# Template register map
Vendor: VendorName Co.Ltd; Series: SeriesName; File version: 1.2
CPU: CM7 r0p1, little endian, MPU, FPU, 4 interrupt priority bits
Registers are 32-bit, read-write, no defined reset value unless marked. A register's access mark holds for its fields unless they carry their own. Offsets are from the block's base; [hi:lo] are bit positions; {n}, {i} and the like mark numbered series; 'fields as' and 'values as' point back to an identical list.

## RCC — Reset And Clock Control
Base 0x400B0000
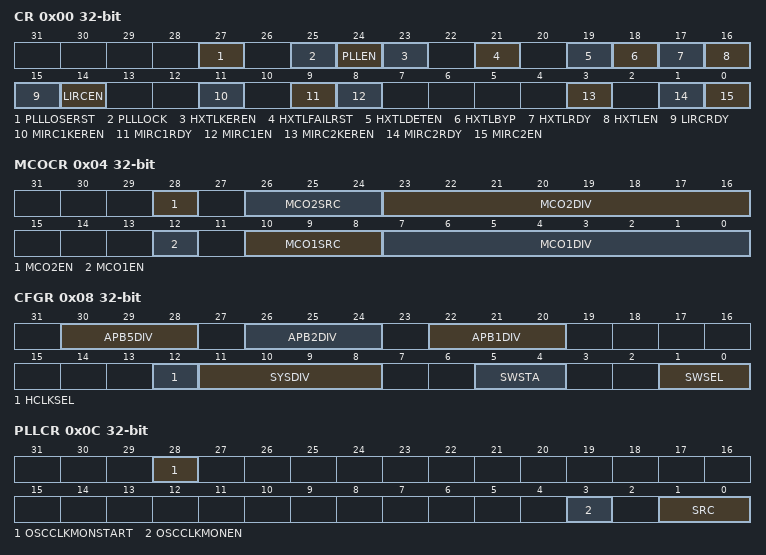
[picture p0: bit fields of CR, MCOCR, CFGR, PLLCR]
0x00 CR — RCC control register
  [27] PLLLOSERST — RCC PLLLOSERST bit: PLL lose of lock reset enable
  [25] PLLLOCK ro — RCC PLLLOCK bit: PLL lock flag
  [24] PLLEN — RCC PLLEN bit: PLL module enable
  [23] HXTLKEREN — RCC HXTLKEREN bit: kernal use HXTL clock oscillator enable
  [21] HXTLFAILRST — RCC HXTLFAILRST bit: HXTL failure reset enable
  [19] HXTLDETEN — RCC HXTLDETEN bit: HXTL clock check module control
  [18] HXTLBYP — RCC HXTLBYP bit: HXTL bypass config
  [17] HXTLRDY ro — RCC HXTLRDY bit: HXTL clock ready flag
  [16] HXTLEN — RCC HXTLEN bit: HXTL clock oscillator enable
  [15] LIRCRDY ro — RCC LIRCRDY bit: LIRC clock ready flag
  [14] LIRCEN — RCC LIRCEN bit: LIRC clock oscillator enable
  [11] MIRC1KEREN — RCC MIRC1KEREN bit: kernal use MIRC1 clock oscillator enable
  [9] MIRC1RDY ro — RCC MIRC1RDY bit: MIRC1 clock ready flag
  [8] MIRC1EN — RCC MIRC1EN bit: MIRC1 clock oscillator enable
  [3] MIRC2KEREN — RCC MIRC2KEREN bit: kernal use MIRC2 clock oscillator enable
  [1] MIRC2RDY ro — RCC MIRC2RDY bit: MIRC2 clock ready flag
  [0] MIRC2EN — RCC MIRC2EN bit: MIRC2 clock oscillator enable
0x04 MCOCR — RCC MCO config register
  [28] MCO2EN — RCC MCO2EN bit: MCO2 clock output enable
  [26:24] MCO2SRC — RCC MCO2SRC[2:0] bit: MCO2 clock output source select
  [23:16] MCO2DIV — RCC MCO2DIV[7:0] bit: MCO2 output frequency division set
  [12] MCO1EN — RCC MCO1EN bit: MCO1 clock output enable
  [10:8] MCO1SRC — RCC MCO1SRC[2:0] bit: MCO1 clock output source select
  [7:0] MCO1DIV — RCC MCO1DIV[7:0] bit: MCO1 output frequency division set
0x08 CFGR — RCC clock config register
  [30:28] APB5DIV — RCC APB5DIV[2:0] bit: APB5 clock frequency division set
  [26:24] APB2DIV — RCC APB2DIV[2:0] bit: APB2 clock frequency division set
  [22:20] APB1DIV — RCC APB1DIV[2:0] bit: APB1 clock frequency division set
  [12] HCLKSEL — RCC HCLKSEL bit: HCLK clock frequency division selection
  [11:8] SYSDIV — RCC SYSDIV[3:0] bit: system clock frequency division set
  [5:4] SWSTA ro — RCC SWSTA[1:0] bit: system clock switch status
  [1:0] SWSEL — RCC SWSEL[1:0] bit: system clock select control
0x0C PLLCR — RCC PLL control register
  [28] OSCCLKMONSTART — RCC OSCCLKMONSTART bit: OSCCLK stop monitor start bit
  [3] OSCCLKMONEN — RCC OSCCLKMONEN bit: OSCCLK stop monitor enable bit
  [1:0] SRC — RCC SRC[1:0] bit: PLL clock input source select
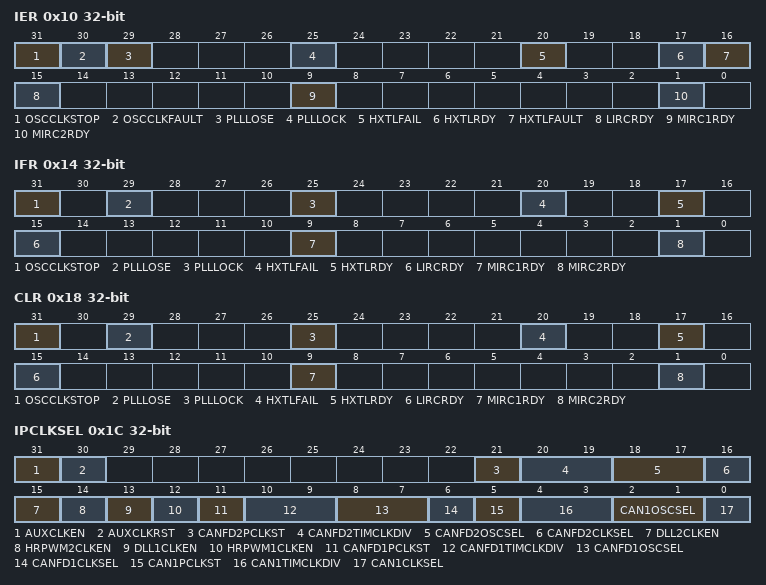
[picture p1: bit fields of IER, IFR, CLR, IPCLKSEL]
0x10 IER — RCC interrupt enable register
  [31] OSCCLKSTOP — RCC OSCCLKSTOP bit: OSCCLK stop interrupt enable
  [30] OSCCLKFAULT — RCC OSCCLKFAULT bit: OSCCLK fault interrupt function select
  [29] PLLLOSE — RCC PLLLOSE bit: PLL lose of lock interrupt enable
  [25] PLLLOCK — RCC PLLLOCK bit: PLL lock interrupt enable
  [20] HXTLFAIL — RCC HXTLFAIL bit: HXTL failure of oscillation interrupt enable
  [17] HXTLRDY — RCC HXTLRDY bit: HXTL ready interrupt enable
  [16] HXTLFAULT — RCC HXTLFAULT bit: HXTL fault interrupt function select
  [15] LIRCRDY — RCC LIRCRDY bit: LIRC ready interrupt enable
  [9] MIRC1RDY — RCC MIRC1RDY bit: MIRC1 ready interrupt enable
  [1] MIRC2RDY — RCC MIRC2RDY bit: MIRC2 ready interrupt enable
0x14 IFR ro — RCC interrupt flag register
  [31] OSCCLKSTOP — RCC OSCCLKSTOP bit: OSCCLK stop interrut flag
  [29] PLLLOSE — RCC PLLLOSE bit: PLL lose of lock flag
  [25] PLLLOCK — RCC PLLLOCK bit: PLL lock interrupt flag
  [20] HXTLFAIL — RCC HXTLFAIL bit: HXTL failure of oscillation interrupt flag
  [17] HXTLRDY — RCC HXTLRDY bit: HXTL ready interrupt flag
  [15] LIRCRDY — RCC LIRCRDY bit: LIRC ready interrupt flag
  [9] MIRC1RDY — RCC MIRC1RDY bit: MIRC1 ready interrupt flag
  [1] MIRC2RDY — RCC MIRC2RDY bit: MIRC2 ready interrupt flag
0x18 CLR — RCC clear interrupt flag register
  [31] OSCCLKSTOP — RCC OSCCLKSTOP bit: OSCCLK stop interrupt flag clear
  [29] PLLLOSE — RCC PLLLOSE bit: PLL lose of lock flag clear
  [25] PLLLOCK — RCC PLLLOCK bit: PLL lock interrupt flag clear
  [20] HXTLFAIL — RCC HXTLFAIL bit: HXTL failure of oscillation interrupt flag clear
  [17] HXTLRDY — RCC HXTLRDY bit: HXTL ready interrupt flag clear
  [15] LIRCRDY — RCC LIRCRDY bit: LIRC ready interrupt flag clear
  [9] MIRC1RDY — RCC MIRC1RDY bit: MIRC1 ready interrupt flag clear
  [1] MIRC2RDY — RCC MIRC2RDY bit: MIRC2 ready interrupt flag clear
0x1C IPCLKSEL — RCC IP clock selection register
  [31] AUXCLKEN — RCC AUXCLKEN bit: AUXCLK input enable
  [30] AUXCLKRST — RCC AUXCLKRST bit: AUXCLK reset
  [21] CANFD2PCLKST ro — RCC CANFD2PCLKST bit: CANFD2 select peripheral clock status
  [20:19] CANFD2TIMCLKDIV — RCC CANFD2TIMCLKDIV[1:0] bit: CANFD2 time stamp tick frequency division
  [18:17] CANFD2OSCSEL — RCC CANFD2OSCSEL[1:0] bit: CANFD2 OSC clock select
  [16] CANFD2CLKSEL — RCC CANFD2CLKSEL bit: CANFD2 peripheral clock select
  [15] DLL2CLKEN — RCC DLL2CLKEN bit: DLL2 clock enable
  [14] HRPWM2CLKEN — RCC HRPWM2CLKEN bit: HRPWM2 clock enable
  [13] DLL1CLKEN — RCC DLL1CLKEN bit: DLL1 clock enable
  [12] HRPWM1CLKEN — RCC HRPWM1CLKEN bit: HRPWM1 clock enable
  [11] CANFD1PCLKST ro — RCC CANFD1PCLKST bit: CANFD1 select peripheral clock status
  [10:9] CANFD1TIMCLKDIV — RCC CANFD1TIMCLKDIV[1:0] bit: CANFD1 time stamp tick frequency division
  [8:7] CANFD1OSCSEL — RCC CANFD1OSCSEL[1:0] bit: CANFD1 OSC clock select
  [6] CANFD1CLKSEL — RCC CANFD1CLKSEL bit: CANFD1 peripheral clock select
  [5] CAN1PCLKST ro — RCC CAN1PCLKST bit: CAN1 select peripheral clock status
  [4:3] CAN1TIMCLKDIV — RCC CAN1TIMCLKDIV[1:0] bit: CAN1 time stamp tick frequency division
  [2:1] CAN1OSCSEL — RCC CAN1OSCSEL[1:0] bit: CAN1 OSC clock select
  [0] CAN1CLKSEL — RCC CAN1CLKSEL bit: CAN1 peripheral clock select
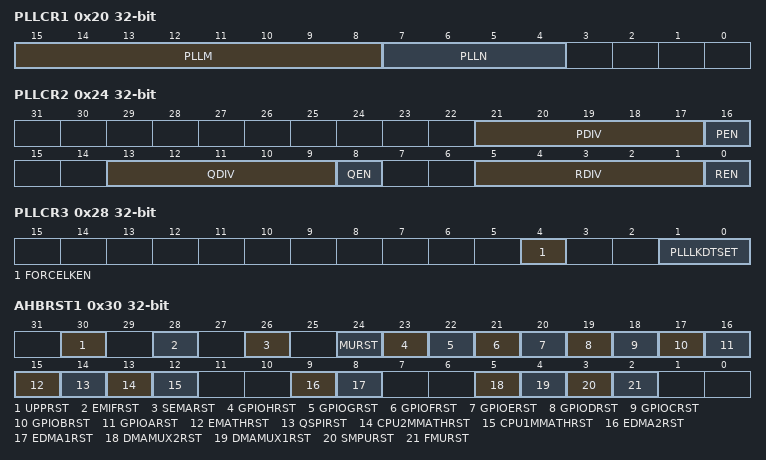
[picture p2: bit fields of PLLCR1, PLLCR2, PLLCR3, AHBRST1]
0x20 PLLCR1 — RCC PLL control register 1
  [15:8] PLLM — RCC PLLM[7:0] bit: PLL VCO frequency multiplication factor select bit
  [7:4] PLLN — RCC PLLN[3:0] bit: PLL input clock frequency division factor select bit
0x24 PLLCR2 — RCC PLL control register 2
  [21:17] PDIV — RCC PDIV[4:0] bit: PLLP output clock frequency division config bit
  [16] PEN — RCC PEN bit: PLLP clock output enable control bit
  [13:9] QDIV — RCC QDIV[4:0] bit: PLLQ output clock frequency division config bit
  [8] QEN — RCC QEN bit: PLLQ clock output enable control bit
  [5:1] RDIV — RCC RDIV[4:0] bit: PLLR output clock frequency division config bit
  [0] REN — RCC REN bit: PLLR clock output enable control bit
0x28 PLLCR3 — RCC PLL control register 3
  [4] FORCELKEN — RCC FORCELKEN bit: PLL force lock enable control bit
  [1:0] PLLLKDTSET — RCC PLLLKDTSET[1:0] bit: PLL lock and lose of lock offset value
0x2C PLLSR1 ro — RCC PLL state register 1
  [2:0] LOCKREFCNT — RCC LOCKREFCNT[2:0] bit: PLL lock finished counter
0x30 AHBRST1 — RCC AHB module reset register 1
  [30] UPPRST — RCC UPPRST bit: UPP module reset
  [28] EMIFRST — RCC EMIFRST bit: EMIF module reset
  [26] SEMARST — RCC SEMARST bit: SEMA module reset
  [24] MURST — RCC MURST bit: MU module reset
  [23] GPIOHRST — RCC GPIOHRST bit: GPIOH module reset
  [22] GPIOGRST — RCC GPIOGRST bit: GPIOG module reset
  [21] GPIOFRST — RCC GPIOFRST bit: GPIOF module reset
  [20] GPIOERST — RCC GPIOERST bit: GPIOE module reset
  [19] GPIODRST — RCC GPIODRST bit: GPIOD module reset
  [18] GPIOCRST — RCC GPIOCRST bit: GPIOC module reset
  [17] GPIOBRST — RCC GPIOBRST bit: GPIOB module reset
  [16] GPIOARST — RCC GPIOARST bit: GPIOA module reset
  [15] EMATHRST — RCC EMATHRST bit: EMATH module reset
  [14] QSPIRST — RCC QSPIRST bit: QSPI module reset
  [13] CPU2MMATHRST — RCC CPU2MMATHRST bit: CPU2MMATH module reset
  [12] CPU1MMATHRST — RCC CPU1MMATHRST bit: CPU1MMATH module reset
  [9] EDMA2RST — RCC EDMA2RST bit: EDMA2 module reset
  [8] EDMA1RST — RCC EDMA1RST bit: EDMA1 module reset
  [5] DMAMUX2RST — RCC DMAMUX2RST bit: DMAMUX2 module reset
  [4] DMAMUX1RST — RCC DMAMUX1RST bit: DMAMUX1 module reset
  [3] SMPURST — RCC SMPURST bit: SMPU module reset
  [2] FMURST — RCC FMURST bit: FMU module reset
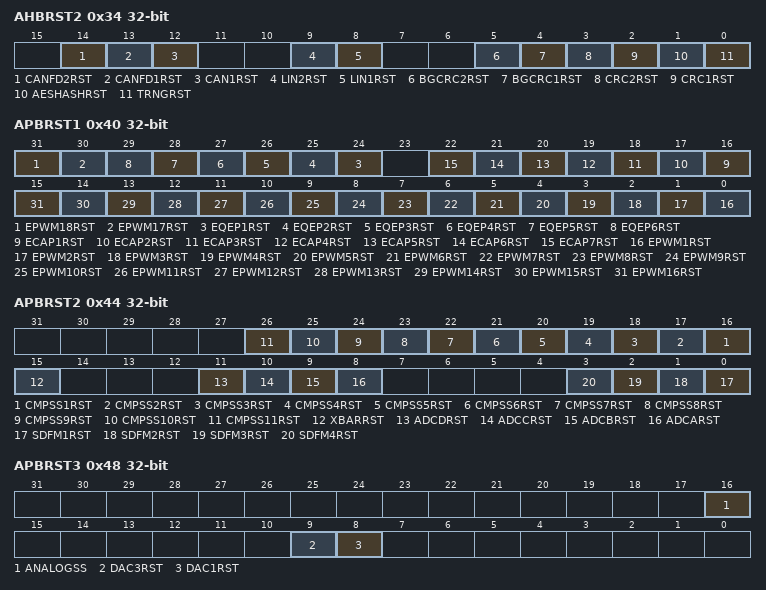
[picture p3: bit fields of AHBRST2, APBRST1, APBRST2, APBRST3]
0x34 AHBRST2 — RCC AHB module reset register 2
  [14] CANFD2RST — RCC CANFD2RST bit: CANFD2 module reset
  [13] CANFD1RST — RCC CANFD1RST bit: CANFD1 module reset
  [12] CAN1RST — RCC CAN1RST bit: CAN1 module reset
  [9] LIN2RST — RCC LIN2RST bit: LIN2 module reset
  [8] LIN1RST — RCC LIN1RST bit: LIN1 module reset
  [5] BGCRC2RST — RCC BGCRC2RST bit: BGCRC2 module reset
  [4] BGCRC1RST — RCC BGCRC1RST bit: BGCRC1 module reset
  [3] CRC2RST — RCC CRC2RST bit: CRC2 module reset
  [2] CRC1RST — RCC CRC1RST bit: CRC1 module reset
  [1] AESHASHRST — RCC AESHASHRST bit: AESHASH module reset
  [0] TRNGRST — RCC TRNGRST bit: RNG module reset
0x40 APBRST1 — RCC APB module reset register 1
  [31] EPWM18RST — RCC EPWM18RST bit: EPWM18 module reset
  [30] EPWM17RST — RCC EPWM17RST bit: EPWM17 module reset
  [n+23] EQEP{n}RST (n=1..6) — RCC EQEP{n}RST bit: EQEP{n} module reset
  [n+15] ECAP{n}RST (n=1..7) — RCC ECAP{n}RST bit: ECAP{n} module reset
  [n-1] EPWM{n}RST (n=1..16) — RCC EPWM{n}RST bit: EPWM{n} module reset
0x44 APBRST2 — RCC APB module reset register 2
  [n+15] CMPSS{n}RST (n=1..11) — RCC CMPSS{n}RST bit: CMPSS{n} module reset
  [15] XBARRST — RCC XBARRST bit: XBAR module reset
  [11] ADCDRST — RCC ADCDRST bit: ADCD module reset
  [10] ADCCRST — RCC ADCCRST bit: ADCC module reset
  [9] ADCBRST — RCC ADCBRST bit: ADCB module reset
  [8] ADCARST — RCC ADCARST bit: ADCA module reset
  [n-1] SDFM{n}RST (n=1..4) — RCC SDFM{n}RST bit: SDFM{n} module reset
0x48 APBRST3 — RCC APB module reset register 3
  [16] ANALOGSS — RCC ANALOGSS bit: ANALOGSS module reset
  [9] DAC3RST — RCC DAC3RST bit: DAC3 module reset
  [8] DAC1RST — RCC DAC1RST bit: DAC1 module reset
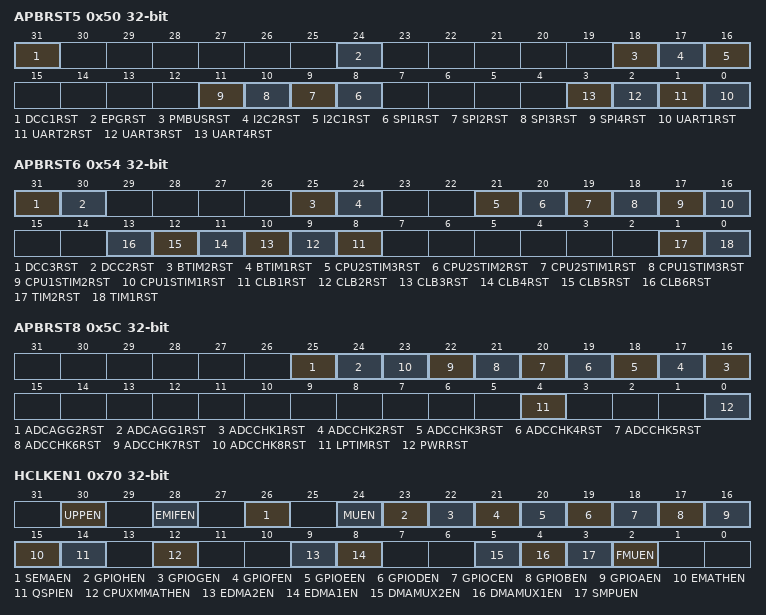
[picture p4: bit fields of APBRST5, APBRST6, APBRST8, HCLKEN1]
0x50 APBRST5 — RCC APB module reset register 5
  [31] DCC1RST — RCC DCC1RST bit: DCC1 module reset
  [24] EPGRST — RCC EPGRST bit: EPG module reset
  [18] PMBUSRST — RCC PMBUSRST bit: PMBUS module reset
  [17] I2C2RST — RCC I2C2RST bit: I2C2 module reset
  [16] I2C1RST — RCC I2C1RST bit: I2C1 module reset
  [n+7] SPI{n}RST (n=1..4) — RCC SPI{n}RST bit: SPI{n} module reset
  [n-1] UART{n}RST (n=1..4) — RCC UART{n}RST bit: UART{n} module reset
0x54 APBRST6 — RCC APB module reset register 6
  [31] DCC3RST — RCC DCC3RST bit: DCC3 module reset
  [30] DCC2RST — RCC DCC2RST bit: DCC2 module reset
  [25] BTIM2RST — RCC BTIM2RST bit: BTIM2 module reset
  [24] BTIM1RST — RCC BTIM1RST bit: BTIM1 module reset
  [21] CPU2STIM3RST — RCC CPU2STIM3RST bit: CPU2STIM3 module reset
  [20] CPU2STIM2RST — RCC CPU2STIM2RST bit: CPU2STIM2 module reset
  [19] CPU2STIM1RST — RCC CPU2STIM1RST bit: CPU2STIM1 module reset
  [18] CPU1STIM3RST — RCC CPU1STIM3RST bit: CPU1STIM3 module reset
  [17] CPU1STIM2RST — RCC CPU1STIM2RST bit: CPU1STIM2 module reset
  [16] CPU1STIM1RST — RCC CPU1STIM1RST bit: CPU1STIM1 module reset
  [n+7] CLB{n}RST (n=1..6) — RCC CLB{n}RST bit: CLB{n} module reset
  [1] TIM2RST — RCC TIM2RST bit: TIM2 module reset
  [0] TIM1RST — RCC TIM1RST bit: TIM1 module reset
0x5C APBRST8 — RCC APB module reset register 8
  [25] ADCAGG2RST — RCC ADCAGG2RST bit: ADC AGG 2 module reset
  [24] ADCAGG1RST — RCC ADCAGG1RST bit: ADC AGG 1 module reset
  [n+15] ADCCHK{n}RST (n=1..8) — RCC ADCCHK{n}RST bit: ADC CHECKER {n} module reset
  [4] LPTIMRST — RCC LPTIMRST bit: LPTIM module reset
  [0] PWRRST — RCC PWRRST bit: PWR module reset
0x70 HCLKEN1 — RCC AHB module clock enable register 1
  [30] UPPEN — RCC UPPEN bit: UPP module clock enable
  [28] EMIFEN — RCC EMIFEN bit: EMIF module clock enable
  [26] SEMAEN — RCC SEMAEN bit: SEMA module clock enable
  [24] MUEN — RCC MUEN bit: MU module clock enable
  [23] GPIOHEN — RCC GPIOHEN bit: GPIOH module clock enable
  [22] GPIOGEN — RCC GPIOGEN bit: GPIOG module clock enable
  [21] GPIOFEN — RCC GPIOFEN bit: GPIOF module clock enable
  [20] GPIOEEN — RCC GPIOEEN bit: GPIOE module clock enable
  [19] GPIODEN — RCC GPIODEN bit: GPIOD module clock enable
  [18] GPIOCEN — RCC GPIOCEN bit: GPIOC module clock enable
  [17] GPIOBEN — RCC GPIOBEN bit: GPIOB module clock enable
  [16] GPIOAEN — RCC GPIOAEN bit: GPIOA module clock enable
  [15] EMATHEN — RCC EMATHEN bit: EMATH module clock enable
  [14] QSPIEN — RCC QSPIEN bit: QSPI module clock enable
  [12] CPUXMMATHEN — RCC CPUXMMATHEN bit: MMATH module clock enable
  [9] EDMA2EN — RCC EDMA2EN bit: EDMA2 module clock enable
  [8] EDMA1EN — RCC EDMA1EN bit: EDMA1 module clock enable
  [5] DMAMUX2EN — RCC DMAMUX2EN bit: DMAMUX2 module clock enable
  [4] DMAMUX1EN — RCC DMAMUX1EN bit: DMAMUX1 module clock enable
  [3] SMPUEN — RCC SMPUEN bit: SMPU module clock enable
  [2] FMUEN — RCC FMUEN bit: FMU module clock enable
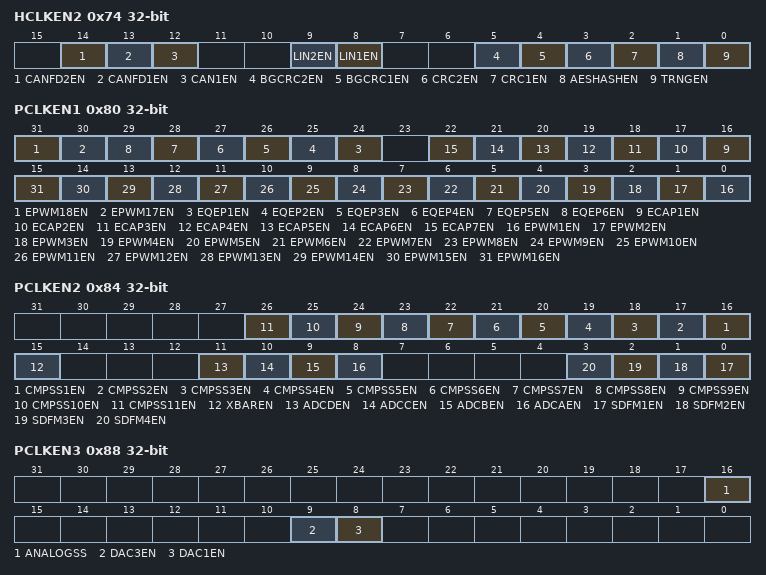
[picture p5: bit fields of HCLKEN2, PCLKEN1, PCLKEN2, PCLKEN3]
0x74 HCLKEN2 — RCC AHB module clock enable register 2
  [14] CANFD2EN — RCC CANFD2EN bit: CANFD2 module clock enable
  [13] CANFD1EN — RCC CANFD1EN bit: CANFD1 module clock enable
  [12] CAN1EN — RCC CAN1EN bit: CAN1 module clock enable
  [9] LIN2EN — RCC LIN2EN bit: LIN2 module clock enable
  [8] LIN1EN — RCC LIN1EN bit: LIN1 module clock enable
  [5] BGCRC2EN — RCC BGCRC2EN bit: BGCRC2 module clock enable
  [4] BGCRC1EN — RCC BGCRC1EN bit: BGCRC1 module clock enable
  [3] CRC2EN — RCC CRC2EN bit: CRC2 module clock enable
  [2] CRC1EN — RCC CRC1EN bit: CRC1 module clock enable
  [1] AESHASHEN — RCC AESHASHEN bit: AESHASH module clock aesenable
  [0] TRNGEN — RCC TRNGEN bit: TRNG module clock rngenable
0x80 PCLKEN1 — RCC APB module clock enable register 1
  [31] EPWM18EN — RCC EPWM18EN bit: EPWM18 module clock enable
  [30] EPWM17EN — RCC EPWM17EN bit: EPWM17 module clock enable
  [n+23] EQEP{n}EN (n=1..6) — RCC EQEP{n}EN bit: EQEP{n} module clock enable
  [n+15] ECAP{n}EN (n=1..7) — RCC ECAP{n}EN bit: ECAP{n} module clock enable
  [n-1] EPWM{n}EN (n=1..16) — RCC EPWM{n}EN bit: EPWM{n} module clock enable
0x84 PCLKEN2 — RCC APB module clock enable register 2
  [n+15] CMPSS{n}EN (n=1..11) — RCC CMPSS{n}EN bit: CMPSS{n} module clock enable
  [15] XBAREN — RCC XBAREN bit: XBAR module clock enable
  [11] ADCDEN — RCC ADCDEN bit: ADCD module clock enable
  [10] ADCCEN — RCC ADCCEN bit: ADCC module clock enable
  [9] ADCBEN — RCC ADCBEN bit: ADCB module clock enable
  [8] ADCAEN — RCC ADCAEN bit: ADCA module clock enable
  [n-1] SDFM{n}EN (n=1..4) — RCC SDFM{n}EN bit: SDFM{n} module clock enable
0x88 PCLKEN3 — RCC APB module clock enable register 3
  [16] ANALOGSS — RCC ANALOGSS bit: ANALOGSS module clock enable
  [9] DAC3EN — RCC DAC3EN bit: DAC3 module clock enable
  [8] DAC1EN — RCC DAC1EN bit: DAC1 module clock enable
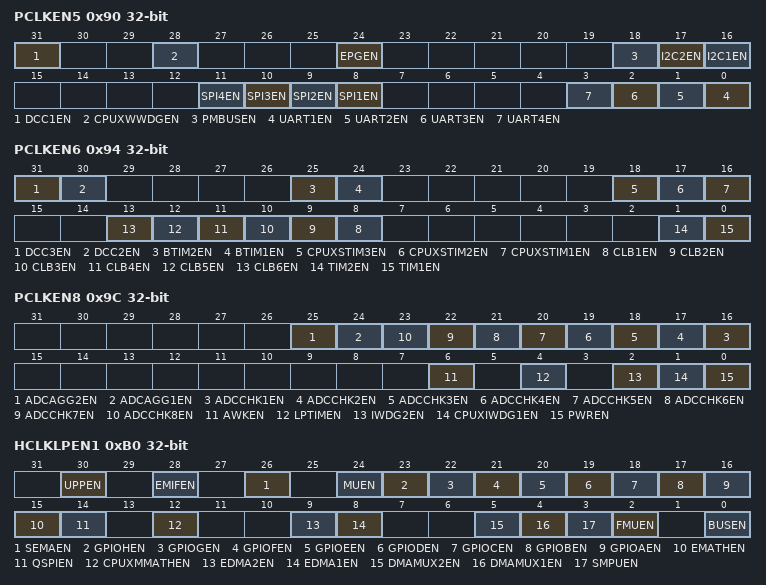
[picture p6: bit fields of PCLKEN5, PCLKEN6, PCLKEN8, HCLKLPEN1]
0x90 PCLKEN5 — RCC APB module clock enable register 5
  [31] DCC1EN — RCC DCC1EN bit: DCC1 module clock enable
  [28] CPUXWWDGEN — RCC CPUXWWDGEN bit: WWDG module clock enable
  [24] EPGEN — RCC EPGEN bit: EPG module clock enable
  [18] PMBUSEN — RCC PMBUSEN bit: PMBUS module clock enable
  [17] I2C2EN — RCC I2C2EN bit: I2C2 module clock enable
  [16] I2C1EN — RCC I2C1EN bit: I2C1 module clock enable
  [n+7] SPI{n}EN (n=1..4) — RCC SPI{n}EN bit: SPI{n} module clock enable
  [n-1] UART{n}EN (n=1..4) — RCC UART{n}EN bit: UART{n} module clock ebable
0x94 PCLKEN6 — RCC APB module clock enable register 6
  [31] DCC3EN — RCC DCC3EN bit: DCC3 module clock enable
  [30] DCC2EN — RCC DCC2EN bit: DCC2 module clock enable
  [25] BTIM2EN — RCC BTIM2EN bit: BTIM2 module clock enable
  [24] BTIM1EN — RCC BTIM1EN bit: BTIM1 module clock enable
  [18] CPUXSTIM3EN — RCC CPUXSTIM3EN bit: STIM3 module clock enable
  [17] CPUXSTIM2EN — RCC CPUXSTIM2EN bit: STIM2 module clock enable
  [16] CPUXSTIM1EN — RCC CPUXSTIM1EN bit: STIM1 module clock enable
  [n+7] CLB{n}EN (n=1..6) — RCC CLB{n}EN bit: CLB{n} module clock enable
  [1] TIM2EN — RCC TIM2EN bit: TIM2 module clock enable
  [0] TIM1EN — RCC TIM1EN bit: TIM1 module clock enable
0x9C PCLKEN8 — RCC APB module clock enable register 8
  [25] ADCAGG2EN — RCC ADCAGG2EN bit: ADC AGG 2 module clock enable
  [24] ADCAGG1EN — RCC ADCAGG1EN bit: ADC AGG 1 module clock enable
  [n+15] ADCCHK{n}EN (n=1..8) — RCC ADCCHK{n}EN bit: ADC CHECKER {n} module clock enable
  [6] AWKEN — RCC AWKEN bit: AWK module clock awkenable
  [4] LPTIMEN — RCC LPTIMEN bit: LPTIM module clock lptimenable
  [2] IWDG2EN — RCC IWDG2EN bit: IWDG2 module clock enable
  [1] CPUXIWDG1EN — RCC CPUXIWDG1EN bit: IWDG1 module clock enable
  [0] PWREN — RCC PWREN bit: PWR module clock pwrenable
0xB0 HCLKLPEN1 — RCC AHB module clock enable in sleep mode register 1
  [30] UPPEN — RCC UPPEN bit: UPP module clock enable in SLEEP mode
  [28] EMIFEN — RCC EMIFEN bit: EMIF module clock enable in SLEEP mode
  [26] SEMAEN — RCC SEMAEN bit: SEMA module clock enable in SLEEP mode
  [24] MUEN — RCC MUEN bit: MU module clock enable in SLEEP mode
  [23] GPIOHEN — RCC GPIOHEN bit: GPIOH module clock enable in SLEEP mode
  [22] GPIOGEN — RCC GPIOGEN bit: GPIOG module clock enable in SLEEP mode
  [21] GPIOFEN — RCC GPIOFEN bit: GPIOF module clock enable in SLEEP mode
  [20] GPIOEEN — RCC GPIOEEN bit: GPIOE module clock enable in SLEEP mode
  [19] GPIODEN — RCC GPIODEN bit: GPIOD module clock enable in SLEEP mode
  [18] GPIOCEN — RCC GPIOCEN bit: GPIOC module clock enable in SLEEP mode
  [17] GPIOBEN — RCC GPIOBEN bit: GPIOB module clock enable in SLEEP mode
  [16] GPIOAEN — RCC GPIOAEN bit: GPIOA module clock enable in SLEEP mode
  [15] EMATHEN — RCC EMATHEN bit: EMATH module clock enable in SLEEP mode
  [14] QSPIEN — RCC QSPIEN bit: QSPI module clock enable in SLEEP mode
  [12] CPUXMMATHEN — RCC CPUXMMATHEN bit: MMATH module clock enable in SLEEP mode
  [9] EDMA2EN — RCC EDMA2EN bit: EDMA2 module clock enable in SLEEP mode
  [8] EDMA1EN — RCC EDMA1EN bit: EDMA1 module clock enable in SLEEP mode
  [5] DMAMUX2EN — RCC DMAMUX2EN bit: DMAMUX2 module clock enable in SLEEP mode
  [4] DMAMUX1EN — RCC DMAMUX1EN bit: DMAMUX1 module clock enable in SLEEP mode
  [3] SMPUEN — RCC SMPUEN bit: SMPU module clock enable in SLEEP mode
  [2] FMUEN — RCC FMUEN bit: FMU module clock enable in SLEEP mode
  [0] BUSEN — RCC BUSEN bit: BUS module clock enable in SLEEP mode
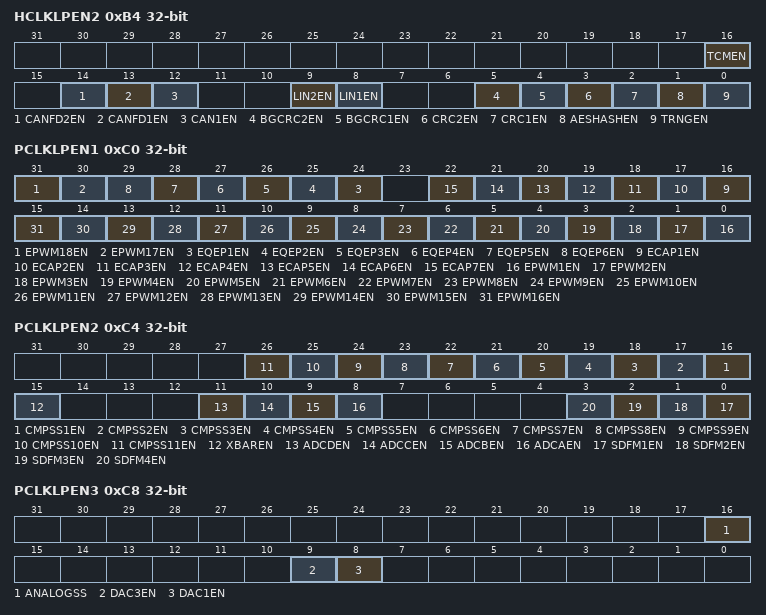
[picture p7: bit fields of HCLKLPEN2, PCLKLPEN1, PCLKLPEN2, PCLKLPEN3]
0xB4 HCLKLPEN2 — RCC AHB module clock enable in sleep mode register 2
  [16] TCMEN — RCC TCMEN bit: TCM module clock enable in SLEEP mode
  [14] CANFD2EN — RCC CANFD2EN bit: CANFD2 module clock enable in SLEEP mode
  [13] CANFD1EN — RCC CANFD1EN bit: CANFD1 module clock enable in SLEEP mode
  [12] CAN1EN — RCC CAN1EN bit: CAN1 module clock enable in SLEEP mode
  [9] LIN2EN — RCC LIN2EN bit: LIN2 module clock enable in SLEEP mode
  [8] LIN1EN — RCC LIN1EN bit: LIN1 module clock enable in SLEEP mode
  [5] BGCRC2EN — RCC BGCRC2EN bit: BGCRC2 module clock enable in SLEEP mode
  [4] BGCRC1EN — RCC BGCRC1EN bit: BGCRC1 module clock enable in SLEEP mode
  [3] CRC2EN — RCC CRC2EN bit: CRC2 module clock enable in SLEEP mode
  [2] CRC1EN — RCC CRC1EN bit: CRC1 module clock enable in SLEEP mode
  [1] AESHASHEN — RCC AESHASHEN bit: AESHASH module clock enable in SLEEP mode
  [0] TRNGEN — RCC TRNGEN bit: TRNG module clock enable in SLEEP mode
0xC0 PCLKLPEN1 — RCC APB module clock enable in sleep mode register 1
  [31] EPWM18EN — RCC EPWM18EN bit: EPWM18 module clock enable in SLEEP mode
  [30] EPWM17EN — RCC EPWM17EN bit: EPWM17 module clock enable in SLEEP mode
  [n+23] EQEP{n}EN (n=1..6) — RCC EQEP{n}EN bit: EQEP{n} module clock enable in SLEEP mode
  [n+15] ECAP{n}EN (n=1..7) — RCC ECAP{n}EN bit: ECAP{n} module clock enable in SLEEP mode
  [n-1] EPWM{n}EN (n=1..16) — RCC EPWM{n}EN bit: EPWM{n} module clock enable in SLEEP mode
0xC4 PCLKLPEN2 — RCC APB module clock enable in sleep mode register 2
  [n+15] CMPSS{n}EN (n=1..11) — RCC CMPSS{n}EN bit: CMPSS{n} module clock enable in SLEEP mode
  [15] XBAREN — RCC XBAREN bit: XBAR module clock enable in SLEEP mode
  [11] ADCDEN — RCC ADCDEN bit: ADCD module clock enable in SLEEP mode
  [10] ADCCEN — RCC ADCCEN bit: ADCC module clock enable in SLEEP mode
  [9] ADCBEN — RCC ADCBEN bit: ADCB module clock enable in SLEEP mode
  [8] ADCAEN — RCC ADCAEN bit: ADCA module clock enable in SLEEP mode
  [n-1] SDFM{n}EN (n=1..4) — RCC SDFM{n}EN bit: SDFM{n} module clock enable in SLEEP mode
0xC8 PCLKLPEN3 — RCC APB module clock enable in sleep mode register 3
  [16] ANALOGSS — RCC ANALOGSS bit: ANALOGSS module clock enable in SLEEP mode
  [9] DAC3EN — RCC DAC3EN bit: DAC3 module clock enable in SLEEP mode
  [8] DAC1EN — RCC DAC1EN bit: DAC1 module clock enable in SLEEP mode
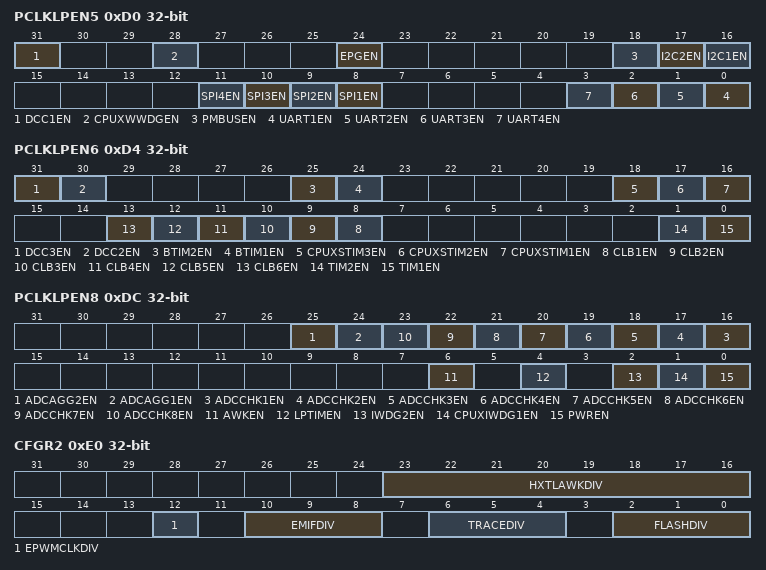
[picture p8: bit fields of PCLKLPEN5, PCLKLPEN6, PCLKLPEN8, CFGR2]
0xD0 PCLKLPEN5 — RCC APB module clock enable in sleep mode register 5
  [31] DCC1EN — RCC DCC1EN bit: DCC1 module clock enable in SLEEP mode
  [28] CPUXWWDGEN — RCC CPUXWWDGEN bit: WWDG module clock enable in SLEEP mode
  [24] EPGEN — RCC EPGEN bit: EPG module clock enable in SLEEP mode
  [18] PMBUSEN — RCC PMBUSEN bit: PMBUS module clock enable in SLEEP mode
  [17] I2C2EN — RCC I2C2EN bit: I2C2 module clock enable in SLEEP mode
  [16] I2C1EN — RCC I2C1EN bit: I2C1 module clock enable in SLEEP mode
  [n+7] SPI{n}EN (n=1..4) — RCC SPI{n}EN bit: SPI{n} module clock enable in SLEEP mode
  [n-1] UART{n}EN (n=1..4) — RCC UART{n}EN bit: UART{n} module clock enable in SLEEP mode
0xD4 PCLKLPEN6 — RCC APB module clock enable in sleep mode register 6
  [31] DCC3EN — RCC DCC3EN bit: DCC3 module clock enable in SLEEP mode
  [30] DCC2EN — RCC DCC2EN bit: DCC2 module clock enable in SLEEP mode
  [25] BTIM2EN — RCC BTIM2EN bit: BTIM2 module clock enable in SLEEP mode
  [24] BTIM1EN — RCC BTIM1EN bit: BTIM1 module clock enable in SLEEP mode
  [18] CPUXSTIM3EN — RCC CPUXSTIM3EN bit: STIM3 module clock enable in SLEEP mode
  [17] CPUXSTIM2EN — RCC CPUXSTIM2EN bit: STIM2 module clock enable in SLEEP mode
  [16] CPUXSTIM1EN — RCC CPUXSTIM1EN bit: STIM1 module clock enable in SLEEP mode
  [n+7] CLB{n}EN (n=1..6) — RCC CLB{n}EN bit: CLB{n} module clock enable in SLEEP mode
  [1] TIM2EN — RCC TIM2EN bit: TIM2 module clock enable in SLEEP mode
  [0] TIM1EN — RCC TIM1EN bit: TIM1 module clock enable in SLEEP mode
0xDC PCLKLPEN8 — RCC APB module clock enable in sleep mode register 8
  [25] ADCAGG2EN — RCC ADCAGG2EN bit: ADC AGG 2 module clock enable in SLEEP mode
  [24] ADCAGG1EN — RCC ADCAGG1EN bit: ADC AGG 1 module clock enable in SLEEP mode
  [n+15] ADCCHK{n}EN (n=1..8) — RCC ADCCHK{n}EN bit: ADC CHECKER {n} module clock enable in SLEEP mode
  [6] AWKEN — RCC AWKEN bit: AWK module clock enable in SLEEP mode
  [4] LPTIMEN — RCC LPTIMEN bit: LPTIM module clock enable in SLEEP mode
  [2] IWDG2EN — RCC IWDG2EN bit: IWDG2 module clock enable in SLEEP mode
  [1] CPUXIWDG1EN — RCC CPUXIWDG1EN bit: IWDG1 module clock enable in SLEEP mode
  [0] PWREN — RCC PWREN bit: PWR module clock enable in SLEEP mode
0xE0 CFGR2 — RCC CLOCK config register 2
  [23:16] HXTLAWKDIV — RCC HXTLAWKDIV[7:0] bit: AWK use HXTL clock frequency division config
  [12] EPWMCLKDIV — RCC EPWMCLKDIV bit: EPWM clock frequency division config
  [10:8] EMIFDIV — RCC EMIFDIV[2:0] bit: EMIF clock frequency division config
  [6:4] TRACEDIV — RCC TRACEDIV[2:0] bit: TRACE clock frequency division config
  [2:0] FLASHDIV — RCC FLASHDIV[2:0] bit: FLASH clock frequency division config
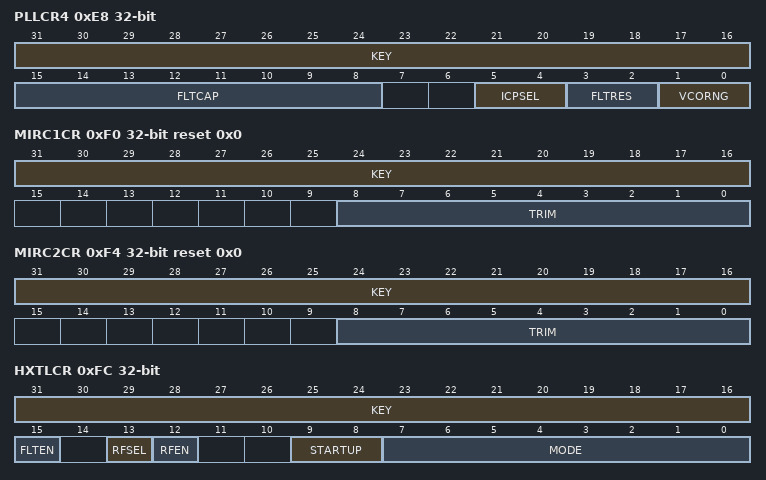
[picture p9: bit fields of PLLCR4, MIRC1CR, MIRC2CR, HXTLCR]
0xE8 PLLCR4 — RCC PLL control register 4
  [31:16] KEY wo — RCC KEY[15:0] bit: only when 0x5A69 is written can this register be written
  [15:8] FLTCAP — RCC FLTCAP[7:0] bit: selection of loop filter capacitor value
  [5:4] ICPSEL — RCC ICPSEL[1:0] bit: charge pump current adjustment
  [3:2] FLTRES — RCC FLTRES[1:0] bit: loop filter R/C adjustment
  [1:0] VCORNG — RCC VCORNG[1:0] bit: VCO operation range selection
0xF0 MIRC1CR reset 0x0 (reset mask 0xFFFFF000) — RCC MIRC1 control register
  [31:16] KEY wo — RCC KEY[15:0] bit: only when 0x5A69 is written can this register be written
  [8:0] TRIM — RCC TRIM[8:0] bit: MIRC1 trim value
0xF4 MIRC2CR reset 0x0 (reset mask 0xFFFFF000) — RCC MIRC2 control register
  [31:16] KEY wo — RCC KEY[15:0] bit: only when 0x5A69 is writte can this register be written
  [8:0] TRIM — RCC TRIM[8:0] bit: MIRC2 trim value
0xFC HXTLCR — RCC HXTL control register
  [31:16] KEY wo — RCC KEY[15:0] bit: only when 0x5A69 is written can this register be written
  [15] FLTEN — RCC FLTEN bit: HXTL output filtering enable
  [13] RFSEL — RCC RFSEL bit: HXTL feedback resistance select
  [12] RFEN — RCC RFEN bit: HXTL feedback resistance enable
  [9:8] STARTUP — RCC STARTUP[1:0] bit: HXTL external 4~32MHz crystal oscillator stability time
  [7:0] MODE — RCC MODE[7:0] bit: HXTL mode select flag
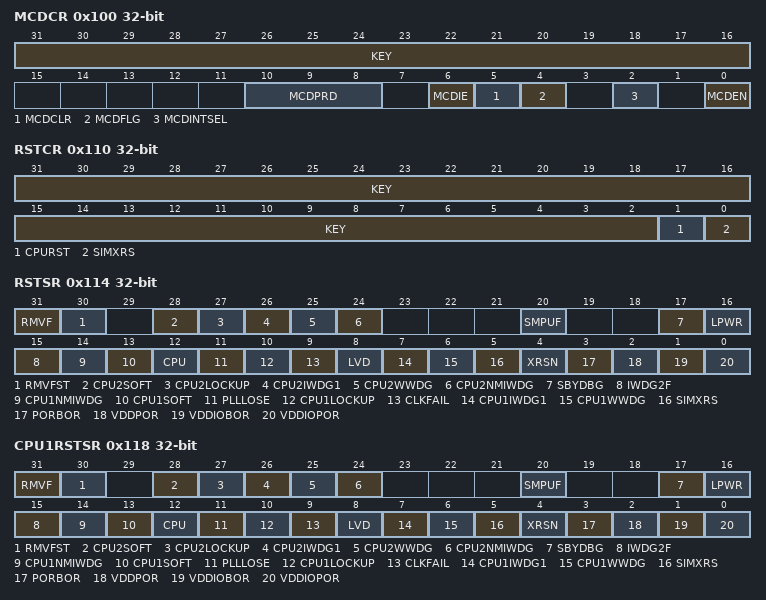
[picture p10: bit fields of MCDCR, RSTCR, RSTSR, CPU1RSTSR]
0x100 MCDCR — RCC MCD control register
  [31:16] KEY wo — RCC KEY[15:0] bit: only when 0x5A69 is written can this register be written
  [10:8] MCDPRD — RCC MCDPRD[2:0] bit: MCD period select
  [6] MCDIE — RCC MCDIE bit: MCD interrupt enable
  [5] MCDCLR — RCC MCDCLR bit: MCD flag clear
  [4] MCDFLG — RCC MCDFLG bit: MCD flag
  [2] MCDINTSEL — RCC MCDINTSEL bit: MCD fault interrupt select
  [0] MCDEN — RCC MCDEN bit: MCD enable
0x110 RSTCR — RCC reset control register
  [31:2] KEY wo — RCC KEY[29:0] bit: only when 0x5A69 is written can this register be written
  [1] CPURST — RCC CPURST bit: register CPU reset
  [0] SIMXRS — RCC SIMXRS bit: register XRS reset
0x114 RSTSR — RCC reset state register
  [31] RMVF — RCC RMVF bit: remove reset flag
  [30] RMVFST ro — RCC RMVFST bit: remove reset flag status
  [28] CPU2SOFT ro — RCC CPU2SOFT bit: CPU2 software reset flag
  [27] CPU2LOCKUP ro — RCC CPU2LOCKUP bit: CPU2 lockup reset flag
  [26] CPU2IWDG1 ro — RCC CPU2IWDG1 bit: CPU2 IWDG1 reset flag
  [25] CPU2WWDG ro — RCC CPU2WWDG bit: CPU2 WWDG reset flag
  [24] CPU2NMIWDG ro — RCC CPU2NMIWDG bit: CPU2 NMIWDG reset flag
  [20] SMPUF ro — RCC SMPUF bit: SMPU reset flag
  [17] SBYDBG ro — RCC SBYDBG bit: standby debug reset flag
  [16] LPWR ro — RCC LPWR bit: low power manager enter reset flag
  [15] IWDG2F ro — RCC IWDG2F bit: IWDG2 reset flag
  [14] CPU1NMIWDG ro — RCC CPU1NMIWDG bit: CPU1 NMIWDG reset flag
  [13] CPU1SOFT ro — RCC CPU1SOFT bit: CPU1 software reset flag
  [12] CPU ro — RCC CPU bit: CPU reset flag
  [11] PLLLOSE ro — RCC PLLLOSE bit: PLL loss of lock reset flag
  [10] CPU1LOCKUP ro — RCC CPU1LOCKUP bit: CPU1 lockup reset flag
  [9] CLKFAIL ro — RCC CLKFAIL bit: clock monitor lose of clock reset flag
  [8] LVD ro — RCC LVD bit: LVD reset flag
  [7] CPU1IWDG1 ro — RCC CPU1IWDG1 bit: CPU1 IWDG1 reset flag
  [6] CPU1WWDG ro — RCC CPU1WWDG bit: CPU1 WWDG reset flag
  [5] SIMXRS ro — RCC SIMXRS bit: Register XRSn reset flag
  [4] XRSN ro — RCC XRSN bit: RESET port reset flag
  [3] PORBOR ro — RCC PORBOR bit: PORBOR reset flag
  [2] VDDPOR ro — RCC VDDPOR bit: VDDPOR reset flag
  [1] VDDIOBOR ro — RCC VDDIOBOR bit: VDDIOBOR reset flag
  [0] VDDIOPOR ro — RCC VDDIOPOR bit: VDDIOPOR reset flag
0x118 CPU1RSTSR ro — CPU1 reset state register
  [31] RMVF — RCC RMVF bit: remove reset flag
  [30] RMVFST — RCC RMVFST bit: remove reset flag status
  [28] CPU2SOFT — RCC CPU2SOFT bit: CPU2 software reset flag
  [27] CPU2LOCKUP — RCC CPU2LOCKUP bit: CPU2 lockup reset flag
  [26] CPU2IWDG1 — RCC CPU2IWDG1 bit: CPU2 IWDG1 reset flag
  [25] CPU2WWDG — RCC CPU2WWDG bit: CPU2 WWDG reset flag
  [24] CPU2NMIWDG — RCC CPU2NMIWDG bit: CPU2 NMIWDG reset flag
  [20] SMPUF — RCC SMPUF bit: SMPU reset flag
  [17] SBYDBG — RCC SBYDBG bit: standby debug reset flag
  [16] LPWR — RCC LPWR bit: low power manager enter reset flag
  [15] IWDG2F — RCC IWDG2F bit: IWDG2 reset flag
  [14] CPU1NMIWDG — RCC CPU1NMIWDG bit: CPU1 NMIWDG reset flag
  [13] CPU1SOFT — RCC CPU1SOFT bit: CPU1 software reset flag
  [12] CPU — RCC CPU bit: CPU reset flag
  [11] PLLLOSE — RCC PLLLOSE bit: PLL loss of lock reset flag
  [10] CPU1LOCKUP — RCC CPU1LOCKUP bit: CPU1 lockup reset flag
  [9] CLKFAIL — RCC CLKFAIL bit: clock monitor lose of clock reset flag
  [8] LVD — RCC LVD bit: LVD reset flag
  [7] CPU1IWDG1 — RCC CPU1IWDG1 bit: CPU1 IWDG1 reset flag
  [6] CPU1WWDG — RCC CPU1WWDG bit: CPU1 WWDG reset flag
  [5] SIMXRS — RCC SIMXRS bit: Register XRSn reset flag
  [4] XRSN — RCC XRSN bit: RESET port reset flag
  [3] PORBOR — RCC PORBOR bit: PORBOR reset flag
  [2] VDDPOR — RCC VDDPOR bit: VDDPOR reset flag
  [1] VDDIOBOR — RCC VDDIOBOR bit: VDDIOBOR reset flag
  [0] VDDIOPOR — RCC VDDIOPOR bit: VDDIOPOR reset flag
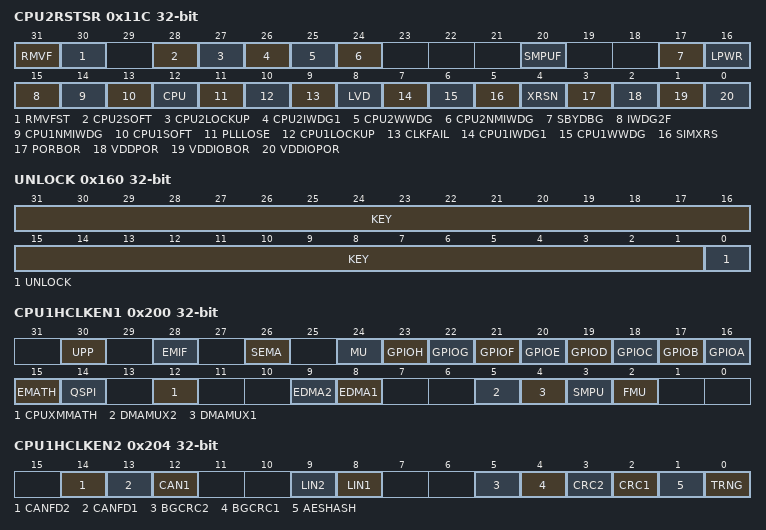
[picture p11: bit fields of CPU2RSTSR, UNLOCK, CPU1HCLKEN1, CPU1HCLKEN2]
0x11C CPU2RSTSR ro — CPU2 reset state register
  fields as CPU1RSTSR
0x160 UNLOCK — RCC write locker register
  [31:1] KEY wo — RCC KEY[30:0] bit: only when 0x2AD5334C is written at high position can this register be written
  [0] UNLOCK — RCC UNLOCK bit: register write protection unlock enable
0x200 CPU1HCLKEN1 ro — CPU1 AHB module enable read only register 1
  [30] UPP — RCC UPP bit: UPP module clock enable
  [28] EMIF — RCC EMIF bit: EMIF module clock enable
  [26] SEMA — RCC SEMA bit: SEMA module clock enable
  [24] MU — RCC MU bit: MU module clock enable
  [23] GPIOH — RCC GPIOH bit: GPIOH module clock enable
  [22] GPIOG — RCC GPIOG bit: GPIOG module clock enable
  [21] GPIOF — RCC GPIOF bit: GPIOF module clock enable
  [20] GPIOE — RCC GPIOE bit: GPIOE module clock enable
  [19] GPIOD — RCC GPIOD bit: GPIOD module clock enable
  [18] GPIOC — RCC GPIOC bit: GPIOC module clock enable
  [17] GPIOB — RCC GPIOB bit: GPIOB module clock enable
  [16] GPIOA — RCC GPIOA bit: GPIOA module clock enable
  [15] EMATH — RCC EMATH bit: EMATH module clock enable
  [14] QSPI — RCC QSPI bit: QSPI module clock enable
  [12] CPUXMMATH — RCC CPUXMMATH bit: MMATH module clock enable
  [9] EDMA2 — RCC EDMA2 bit: EDMA2 module clock enable
  [8] EDMA1 — RCC EDMA1 bit: EDMA1 module clock enable
  [5] DMAMUX2 — RCC DMAMUX2 bit: DMAMUX2 module clock enable
  [4] DMAMUX1 — RCC DMAMUX1 bit: DMAMUX1 module clock enable
  [3] SMPU — RCC SMPU bit: SMPU module clock enable
  [2] FMU — RCC FMU bit: FMU module clock enable
0x204 CPU1HCLKEN2 ro — CPU1 AHB module enable read only register 2
  [14] CANFD2 — RCC CANFD2 bit: CANFD2 module clock enable
  [13] CANFD1 — RCC CANFD1 bit: CANFD1 module clock enable
  [12] CAN1 — RCC CAN1 bit: CAN1 module clock enable
  [9] LIN2 — RCC LIN2 bit: LIN2 module clock enable
  [8] LIN1 — RCC LIN1 bit: LIN1 module clock enable
  [5] BGCRC2 — RCC BGCRC2 bit: BGCRC2 module clock enable
  [4] BGCRC1 — RCC BGCRC1 bit: BGCRC1 module clock enable
  [3] CRC2 — RCC CRC2 bit: CRC2 module clock enable
  [2] CRC1 — RCC CRC1 bit: CRC1 module clock enable
  [1] AESHASH — RCC AESHASH bit: AESHASH module clock aesenable
  [0] TRNG — RCC TRNG bit: TRNG module clock rngenable
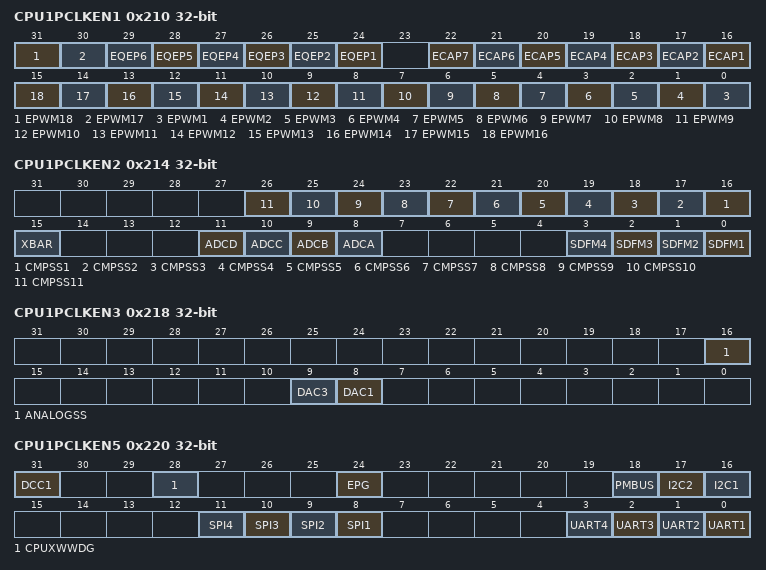
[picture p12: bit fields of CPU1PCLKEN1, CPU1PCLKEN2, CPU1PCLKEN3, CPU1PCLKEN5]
0x210 CPU1PCLKEN1 ro — CPU1 APB module enable read only register 1
  [31] EPWM18 — RCC EPWM18 bit: EPWM18 module clock enable
  [30] EPWM17 — RCC EPWM17 bit: EPWM17 module clock enable
  [n+23] EQEP{n} (n=1..6) — RCC EQEP{n} bit: EQEP{n} module clock enable
  [n+15] ECAP{n} (n=1..7) — RCC ECAP{n} bit: ECAP{n} module clock enable
  [n-1] EPWM{n} (n=1..16) — RCC EPWM{n} bit: EPWM{n} module clock enable
0x214 CPU1PCLKEN2 ro — CPU1 APB module enable read only register 2
  [n+15] CMPSS{n} (n=1..11) — RCC CMPSS{n} bit: CMPSS{n} module clock enable
  [15] XBAR — RCC XBAR bit: XBAR module clock xbarenable
  [11] ADCD — RCC ADCD bit: ADCD module clock adcdenable
  [10] ADCC — RCC ADCC bit: ADCC module clock adccenable
  [9] ADCB — RCC ADCB bit: ADCB module clock adcbenable
  [8] ADCA — RCC ADCA bit: ADCA module clock adcaenable
  [n-1] SDFM{n} (n=1..4) — RCC SDFM{n} bit: SDFM{n} module clock enable
0x218 CPU1PCLKEN3 ro — CPU1 APB module enable read only register 3
  [16] ANALOGSS — RCC ANALOGSS bit: ANALOGSS module clock enable
  [9] DAC3 — RCC DAC3 bit: DAC3 module clock enable
  [8] DAC1 — RCC DAC1 bit: DAC1 module clock enable
0x220 CPU1PCLKEN5 ro — CPU1 APB module enable read only register 5
  [31] DCC1 — RCC DCC1 bit: DCC1 module clock enable
  [28] CPUXWWDG — RCC CPUXWWDG bit: WWDG module clock enable
  [24] EPG — RCC EPG bit: EPG module clock enable
  [18] PMBUS — RCC PMBUS bit: PMBUS module clock enable
  [17] I2C2 — RCC I2C2 bit: I2C2 module clock enable
  [16] I2C1 — RCC I2C1 bit: I2C1 module clock enable
  [n+7] SPI{n} (n=1..4) — RCC SPI{n} bit: SPI{n} module clock enable
  [n-1] UART{n} (n=1..4) — RCC UART{n} bit: UART{n} module clock enable
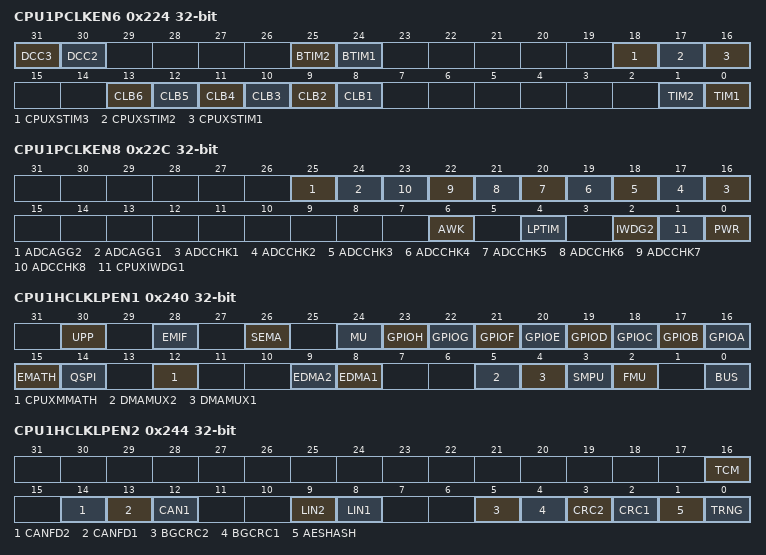
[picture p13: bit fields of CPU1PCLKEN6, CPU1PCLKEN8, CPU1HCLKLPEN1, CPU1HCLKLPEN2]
0x224 CPU1PCLKEN6 ro — CPU1 APB module enable read only register 6
  [31] DCC3 — RCC DCC3 bit: DCC3 module clock enable
  [30] DCC2 — RCC DCC2 bit: DCC2 module clock enable
  [25] BTIM2 — RCC BTIM2 bit: BTIM2 module clock enable
  [24] BTIM1 — RCC BTIM1 bit: BTIM1 module clock enable
  [18] CPUXSTIM3 — RCC CPUXSTIM3 bit: STIM3 module clock enable
  [17] CPUXSTIM2 — RCC CPUXSTIM2 bit: STIM2 module clock enable
  [16] CPUXSTIM1 — RCC CPUXSTIM1 bit: STIM1 module clock enable
  [n+7] CLB{n} (n=1..6) — RCC CLB{n} bit: CLB{n} module clock enable
  [1] TIM2 — RCC TIM2 bit: TIM2 module clock enable
  [0] TIM1 — RCC TIM1 bit: TIM1 module clock enable
0x22C CPU1PCLKEN8 ro — CPU1 APB module enable read only register 8
  [25] ADCAGG2 — RCC ADCAGG2 bit: ADC AGG 2 module clock enable
  [24] ADCAGG1 — RCC ADCAGG1 bit: ADC AGG 1 module clock enable
  [n+15] ADCCHK{n} (n=1..8) — RCC ADCCHK{n} bit: ADC CHECKER {n} module clock enable
  [6] AWK — RCC AWK bit: AWK module clock enable
  [4] LPTIM — RCC LPTIM bit: LPTIM module clock enable
  [2] IWDG2 — RCC IWDG2 bit: IWDG2 module clock enable
  [1] CPUXIWDG1 — RCC CPUXIWDG1 bit: IWDG1 module clock enable
  [0] PWR — RCC PWR bit: PWR module clock enable
0x240 CPU1HCLKLPEN1 ro — CPU1 AHB module enable in sleep mode read only register 1
  [30] UPP — RCC UPP bit: UPP module clock enable in SLEEP mode
  [28] EMIF — RCC EMIF bit: EMIF module clock enable in SLEEP mode
  [26] SEMA — RCC SEMA bit: SEMA module clock enable in SLEEP mode
  [24] MU — RCC MU bit: MU module clock enable in SLEEP mode
  [23] GPIOH — RCC GPIOH bit: GPIOH module clock enable in SLEEP mode
  [22] GPIOG — RCC GPIOG bit: GPIOG module clock enable in SLEEP mode
  [21] GPIOF — RCC GPIOF bit: GPIOF module clock enable in SLEEP mode
  [20] GPIOE — RCC GPIOE bit: GPIOE module clock enable in SLEEP mode
  [19] GPIOD — RCC GPIOD bit: GPIOD module clock enable in SLEEP mode
  [18] GPIOC — RCC GPIOC bit: GPIOC module clock enable in SLEEP mode
  [17] GPIOB — RCC GPIOB bit: GPIOB module clock enable in SLEEP mode
  [16] GPIOA — RCC GPIOA bit: GPIOA module clock enable in SLEEP mode
  [15] EMATH — RCC EMATH bit: EMATH module clock enable in SLEEP mode
  [14] QSPI — RCC QSPI bit: QSPI module clock enable in SLEEP mode
  [12] CPUXMMATH — RCC CPUXMMATH bit: MMATH module clock enable in SLEEP mode
  [9] EDMA2 — RCC EDMA2 bit: EDMA2 module clock enable in SLEEP mode
  [8] EDMA1 — RCC EDMA1 bit: EDMA1 module clock enable in SLEEP mode
  [5] DMAMUX2 — RCC DMAMUX2 bit: DMAMUX2 module clock enable in SLEEP mode
  [4] DMAMUX1 — RCC DMAMUX1 bit: DMAMUX1 module clock enable in SLEEP mode
  [3] SMPU — RCC SMPU bit: SMPU module clock enable in SLEEP mode
  [2] FMU — RCC FMU bit: FMU module clock enable in SLEEP mode
  [0] BUS — RCC BUS bit: BUS module clock enable in SLEEP mode
0x244 CPU1HCLKLPEN2 ro — CPU1 AHB module enable in sleep mode read only register 2
  [16] TCM — RCC TCM bit: TCM module clock enable in SLEEP mode
  [14] CANFD2 — RCC CANFD2 bit: CANFD2 module clock enable in SLEEP mode
  [13] CANFD1 — RCC CANFD1 bit: CANFD1 module clock enable in SLEEP mode
  [12] CAN1 — RCC CAN1 bit: CAN1 module clock enable in SLEEP mode
  [9] LIN2 — RCC LIN2 bit: LIN2 module clock enable in SLEEP mode
  [8] LIN1 — RCC LIN1 bit: LIN1 module clock enable in SLEEP mode
  [5] BGCRC2 — RCC BGCRC2 bit: BGCRC2 module clock enable in SLEEP mode
  [4] BGCRC1 — RCC BGCRC1 bit: BGCRC1 module clock enable in SLEEP mode
  [3] CRC2 — RCC CRC2 bit: CRC2 module clock enable in SLEEP mode
  [2] CRC1 — RCC CRC1 bit: CRC1 module clock enable in SLEEP mode
  [1] AESHASH — RCC AESHASH bit: AESHASH module clock enable in SLEEP mode
  [0] TRNG — RCC TRNG bit: TRNG module clock enable in SLEEP mode
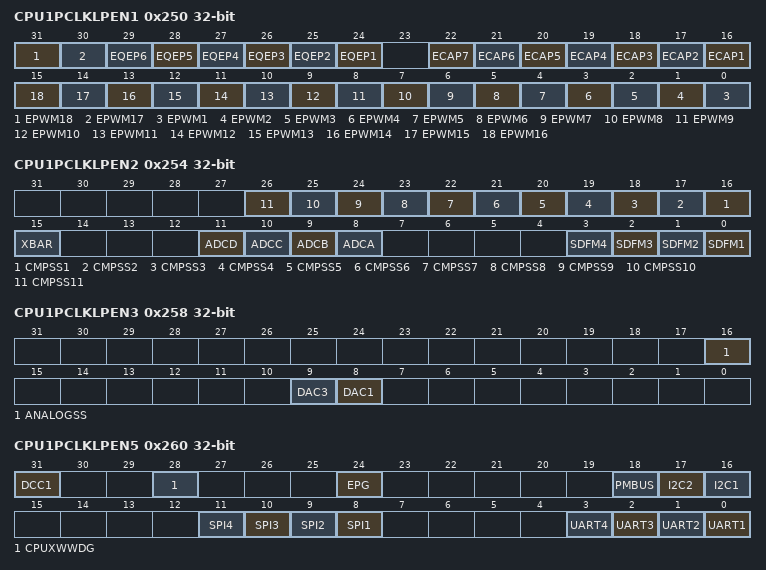
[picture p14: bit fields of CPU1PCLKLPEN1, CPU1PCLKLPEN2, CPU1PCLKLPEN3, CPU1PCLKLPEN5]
0x250 CPU1PCLKLPEN1 ro — CPU1 APB module enable in sleep mode read only register 1
  [31] EPWM18 — RCC EPWM18 bit: EPWM18 module clock enable in SLEEP mode
  [30] EPWM17 — RCC EPWM17 bit: EPWM17 module clock enable in SLEEP mode
  [n+23] EQEP{n} (n=1..6) — RCC EQEP{n} bit: EQEP{n} module clock enable in SLEEP mode
  [n+15] ECAP{n} (n=1..7) — RCC ECAP{n} bit: ECAP{n} module clock enable in SLEEP mode
  [n-1] EPWM{n} (n=1..16) — RCC EPWM{n} bit: EPWM{n} module clock enable in SLEEP mode
0x254 CPU1PCLKLPEN2 ro — CPU1 APB module enable in sleep mode read only register 2
  [n+15] CMPSS{n} (n=1..11) — RCC CMPSS{n} bit: CMPSS{n} module clock enable in SLEEP mode
  [15] XBAR — RCC XBAR bit: XBAR module clock enable in SLEEP mode
  [11] ADCD — RCC ADCD bit: ADCD module clock enable in SLEEP mode
  [10] ADCC — RCC ADCC bit: ADCC module clock enable in SLEEP mode
  [9] ADCB — RCC ADCB bit: ADCB module clock enable in SLEEP mode
  [8] ADCA — RCC ADCA bit: ADCA module clock enable in SLEEP mode
  [n-1] SDFM{n} (n=1..4) — RCC SDFM{n} bit: SDFM{n} module clock enable in SLEEP mode
0x258 CPU1PCLKLPEN3 ro — CPU1 APB module enable in sleep mode read only register 3
  [16] ANALOGSS — RCC ANALOGSS bit: ANALOGSS module clock enable in SLEEP mode
  [9] DAC3 — RCC DAC3 bit: DAC3 module clock enable in SLEEP mode
  [8] DAC1 — RCC DAC1 bit: DAC1 module clock enable in SLEEP mode
0x260 CPU1PCLKLPEN5 ro — CPU1 APB module enable in sleep mode read only register 5
  [31] DCC1 — RCC DCC1 bit: DCC1 module clock enable in SLEEP mode
  [28] CPUXWWDG — RCC CPUXWWDG bit: WWDG module clock enable in SLEEP mode
  [24] EPG — RCC EPG bit: EPG module clock enable in SLEEP mode
  [18] PMBUS — RCC PMBUS bit: PMBUS module clock enable in SLEEP mode
  [17] I2C2 — RCC I2C2 bit: I2C2 module clock enable in SLEEP mode
  [16] I2C1 — RCC I2C1 bit: I2C1 module clock enable in SLEEP mode
  [n+7] SPI{n} (n=1..4) — RCC SPI{n} bit: SPI{n} module clock enable in SLEEP mode
  [n-1] UART{n} (n=1..4) — RCC UART{n} bit: UART{n} module clock enable in SLEEP mode
0x264 CPU1PCLKLPEN6 ro — CPU1 APB module enable in sleep mode read only register 6
  [31] DCC3 — RCC DCC3 bit: DCC3 module clock enable in SLEEP mode
  [30] DCC2 — RCC DCC2 bit: DCC2 module clock enable in SLEEP mode
  [25] BTIM2 — RCC BTIM2 bit: BTIM2 module clock enable in SLEEP mode
  [24] BTIM1 — RCC BTIM1 bit: BTIM1 module clock enable in SLEEP mode
  [18] CPUXSTIM3 — RCC CPUXSTIM3 bit: STIM3 module clock enable in SLEEP mode
  [17] CPUXSTIM2 — RCC CPUXSTIM2 bit: STIM2 module clock enable in SLEEP mode
  [16] CPUXSTIM1 — RCC CPUXSTIM1 bit: STIM1 module clock enable in SLEEP mode
  [n+7] CLB{n} (n=1..6) — RCC CLB{n} bit: CLB{n} module clock enable in SLEEP mode
  [1] TIM2 — RCC TIM2 bit: TIM2 module clock enable in SLEEP mode
  [0] TIM1 — RCC TIM1 bit: TIM1 module clock enable in SLEEP mode
0x26C CPU1PCLKLPEN8 ro — CPU1 APB module enable in sleep mode read only register 8
  [25] ADCAGG2 — RCC ADCAGG2 bit: ADC AGG 2 module clock enable in SLEEP mode
  [24] ADCAGG1 — RCC ADCAGG1 bit: ADC AGG 1 module clock enable in SLEEP mode
  [n+15] ADCCHK{n} (n=1..8) — RCC ADCCHK{n} bit: ADC CHECKER {n} module clock enable in SLEEP mode
  [6] AWK — RCC AWK bit: AWK module clock enable in SLEEP mode
  [4] LPTIM — RCC LPTIM bit: LPTIM module clock enable in SLEEP mode
  [2] IWDG2 — RCC IWDG2 bit: IWDG2 module clock enable in SLEEP mode
  [1] CPUXIWDG1 — RCC CPUXIWDG1 bit: IWDG1 module clock enable in SLEEP mode
  [0] PWR — RCC PWR bit: PWR module clock enable in SLEEP mode
0x280 CPU2HCLKEN1 ro — CPU2 AHB module enable read only register 1
  fields as CPU1HCLKEN1
0x284 CPU2HCLKEN2 ro — CPU2 AHB module enable read only register 2
  fields as CPU1HCLKEN2
0x290 CPU2PCLKEN1 ro — CPU2 APB module enable read only register 1
  fields as CPU1PCLKEN1
0x294 CPU2PCLKEN2 ro — CPU2 APB module enable read only register 2
  [n+15] CMPSS{n} (n=1..11) — RCC CMPSS{n} bit: CMPSS{n} module clock enable
  [15] XBAR — RCC XBAR bit: XBAR module clock enable
  [11] ADCD — RCC ADCD bit: ADCD module clock enable
  [10] ADCC — RCC ADCC bit: ADCC module clock enable
  [9] ADCB — RCC ADCB bit: ADCB module clock enable
  [8] ADCA — RCC ADCA bit: ADCA module clock enable
  [n-1] SDFM{n} (n=1..4) — RCC SDFM{n} bit: SDFM{n} module clock enable
0x298 CPU2PCLKEN3 ro — CPU2 APB module enable read only register 3
  fields as CPU1PCLKEN3
0x2A0 CPU2PCLKEN5 ro — CPU2 APB module enable(read only) register 5
  fields as CPU1PCLKEN5
0x2A4 CPU2PCLKEN6 ro — CPU2 APB module enable read only register 6
  fields as CPU1PCLKEN6
0x2AC CPU2PCLKEN8 ro — CPU2 APB module enable read only register 8
  fields as CPU1PCLKEN8
0x2C0 CPU2HCLKLPEN1 ro — CPU2 AHB module enable in sleep mode read only register 1
  [30] UPP — RCC UPP bit: UPP module clock enable in SLEEP mode
  [28] EMIF — RCC EMIF bit: EMIF module clock enable in SLEEP mode
  [26] SEMA — RCC SEMA bit: SEMA module clock enable in SLEEP mode
  [24] MU — RCC MU bit: MU module clock enable in SLEEP mode
  [23] GPIOH — RCC GPIOH bit: GPIOH module clock enable in SLEEP mode
  [22] GPIOG — RCC GPIOG bit: GPIOG module clock enable in SLEEP mode
  [21] GPIOF — RCC GPIOF bit: GPIOF module clock enable in SLEEP mode
  [20] GPIOE — RCC GPIOE bit: GPIOE module clock enable in SLEEP mode
  [19] GPIOD — RCC GPIOD bit: GPIOD module clock enable in SLEEP mode
  [18] GPIOC — RCC GPIOC bit: GPIOC module clock enable in SLEEP mode
  [17] GPIOB — RCC GPIOB bit: GPIOB module clock enable in SLEEP mode
  [16] GPIOA — RCC GPIOA bit: GPIOA module clock enable in SLEEP mode
  [15] EMATH — RCC EMATH bit: EMATH module clock enable in SLEEP mode
  [14] QSPI — RCC QSPI bit: QSPI module clock enable in SLEEP mode
  [12] CPUXMMATH — RCC CPUXMMATH bit: MMATH module clock enable in SLEEP mode
  [9] EDMA2 — RCC EDMA2 bit: EDMA2 module clock enable in SLEEP mode
  [8] EDMA1 — RCC EDMA1 bit: EDMA1 module clock enable in SLEEP mode
  [5] DMAMUX2 — RCC DMAMUX2 bit: DMAMUX2 module clock enable in SLEEP mode
  [4] DMAMUX1 — RCC DMAMUX1 bit: DMAMUX1 module clock enable in SLEEP mode
  [3] SMPU — RCC SMPU bit: SMPU module clock enable in SLEEP mode
  [2] FMP — RCC FMP bit: FMP module clock enable in SLEEP mode
  [0] BUS — RCC BUS bit: BUS module clock enable in SLEEP mode
0x2C4 CPU2HCLKLPEN2 ro — CPU2 AHB module enable in sleep mode read only register 2
  fields as CPU1HCLKLPEN2
0x2D0 CPU2PCLKLPEN1 ro — CPU2 APB module enable in sleep mode read only register 1
  fields as CPU1PCLKLPEN1
0x2D4 CPU2PCLKLPEN2 ro — CPU2 APB module enable in sleep mode read only register 2
  fields as CPU1PCLKLPEN2
0x2D8 CPU2PCLKLPEN3 ro — CPU2 APB module enable in sleep mode read only register 3
  fields as CPU1PCLKLPEN3
0x2E0 CPU2PCLKLPEN5 ro — CPU2 APB module enable in sleep mode read only register 5
  fields as CPU1PCLKLPEN5
0x2E4 CPU2PCLKLPEN6 ro — CPU2 APB module enable in sleep mode read only register 6
  fields as CPU1PCLKLPEN6
0x2EC CPU2PCLKLPEN8 ro — CPU2 APB module enable in sleep mode read only register 8
  fields as CPU1PCLKLPEN8
